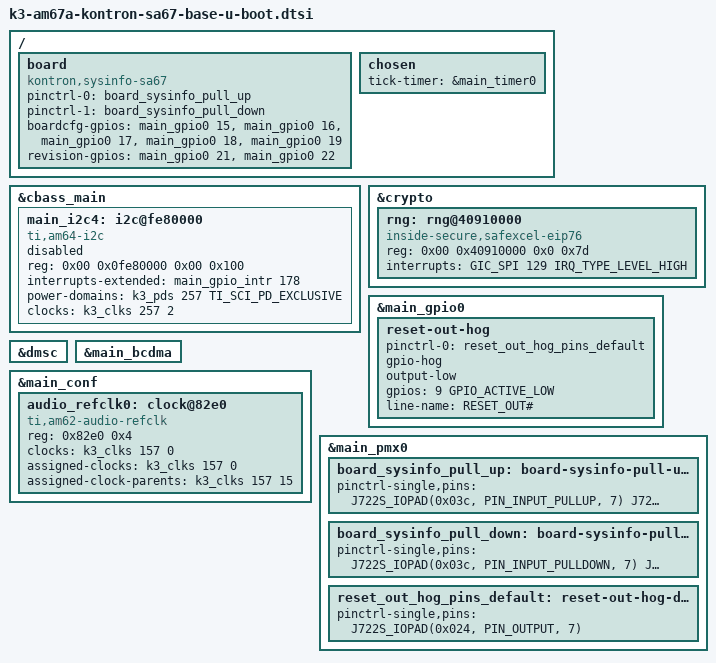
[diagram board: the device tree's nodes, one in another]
// SPDX-License-Identifier: GPL-2.0
/*
 * Copyright (c) 2025 Kontron Europe GmbH
 */

#include "k3-am67a-kontron-sa67-binman.dtsi"

/ {
	board {
		compatible = "kontron,sysinfo-sa67";

		pinctrl-names = "pull-up", "pull-down";
		pinctrl-0 = <&board_sysinfo_pull_up>;
		pinctrl-1 = <&board_sysinfo_pull_down>;

		boardcfg-gpios = <&main_gpio0 15 GPIO_ACTIVE_HIGH>,
				 <&main_gpio0 16 GPIO_ACTIVE_HIGH>,
				 <&main_gpio0 17 GPIO_ACTIVE_HIGH>,
				 <&main_gpio0 18 GPIO_ACTIVE_HIGH>,
				 <&main_gpio0 19 GPIO_ACTIVE_HIGH>;
		revision-gpios = <&main_gpio0 21 GPIO_ACTIVE_HIGH>,
				 <&main_gpio0 22 GPIO_ACTIVE_HIGH>;
		bootph-all;
	};

	chosen {
		tick-timer = &main_timer0;
	};
};

/* can be removed when upstream soc dtsi is updated */
&cbass_main {
	main_i2c4: i2c@fe80000 {
		compatible = "ti,am64-i2c", "ti,omap4-i2c";
		reg = <0x00 0x0fe80000 0x00 0x100>;
		interrupts-extended = <&main_gpio_intr 178>;
		#address-cells = <1>;
		#size-cells = <0>;
		power-domains = <&k3_pds 257 TI_SCI_PD_EXCLUSIVE>;
		clocks = <&k3_clks 257 2>;
		clock-names = "fck";
		status = "disabled";
	};
};

&crypto {
	rng: rng@40910000 {
		compatible = "inside-secure,safexcel-eip76";
		reg = <0x00 0x40910000 0x0 0x7d>;
		interrupts = <GIC_SPI 129 IRQ_TYPE_LEVEL_HIGH>;
	};
};

&main_gpio0 {
	reset-out-hog {
		pinctrl-names = "default";
		pinctrl-0 = <&reset_out_hog_pins_default>;
		gpio-hog;
		output-low;
		gpios = <9 GPIO_ACTIVE_LOW>;
		line-name = "RESET_OUT#";
	};
};

&dmsc {
	bootph-pre-ram;
};

&main_bcdma {
	bootph-pre-ram;
};

/* can be removed when upstream soc dtsi is updated */
&main_conf {
	audio_refclk0: clock@82e0 {
		compatible = "ti,am62-audio-refclk";
		reg = <0x82e0 0x4>;
		clocks = <&k3_clks 157 0>;
		assigned-clocks = <&k3_clks 157 0>;
		assigned-clock-parents = <&k3_clks 157 15>;
		#clock-cells = <0>;
	};
};

/* can be removed when upstream soc dtsi is updated */
&main_pmx0 {
	/delete-property/ pinctrl-single,gpio-range;
	/delete-node/ gpio-range;
};

&main_pmx0 {
	bootph-all;

	board_sysinfo_pull_up: board-sysinfo-pull-up-pins {
		pinctrl-single,pins = <
			J722S_IOPAD(0x03c, PIN_INPUT_PULLUP, 7)		/* (R22) GPNC9_AD0.GPIO0_15 */
			J722S_IOPAD(0x040, PIN_INPUT_PULLUP, 7)		/* (R23) GPNC9_AD1.GPIO0_16 */
			J722S_IOPAD(0x044, PIN_INPUT_PULLUP, 7)		/* (R26) GPNC9_AD2.GPIO0_17 */
			J722S_IOPAD(0x048, PIN_INPUT_PULLUP, 7)		/* (T27) GPNC9_AD3.GPIO0_18 */
			J722S_IOPAD(0x04c, PIN_INPUT_PULLUP, 7)		/* (T25) GPNC9_AD4.GPIO0_19 */
			J722S_IOPAD(0x050, PIN_INPUT_PULLUP, 7)		/* (T24) GPNC9_AD5.GPIO0_20 */
			J722S_IOPAD(0x054, PIN_INPUT_PULLUP, 7)		/* (T21) GPNC9_AD6.GPIO0_21 */
			J722S_IOPAD(0x058, PIN_INPUT_PULLUP, 7)		/* (T22) GPNC9_AD7.GPIO0_22 */
		>;
		bootph-all;
	};

	board_sysinfo_pull_down: board-sysinfo-pull-down-pins {
		pinctrl-single,pins = <
			J722S_IOPAD(0x03c, PIN_INPUT_PULLDOWN, 7)	/* (R22) GPNC9_AD0.GPIO0_15 */
			J722S_IOPAD(0x040, PIN_INPUT_PULLDOWN, 7)	/* (R23) GPNC9_AD1.GPIO0_16 */
			J722S_IOPAD(0x044, PIN_INPUT_PULLDOWN, 7)	/* (R26) GPNC9_AD2.GPIO0_17 */
			J722S_IOPAD(0x048, PIN_INPUT_PULLDOWN, 7)	/* (T27) GPNC9_AD3.GPIO0_18 */
			J722S_IOPAD(0x04c, PIN_INPUT_PULLDOWN, 7)	/* (T25) GPNC9_AD4.GPIO0_19 */
			J722S_IOPAD(0x050, PIN_INPUT_PULLDOWN, 7)	/* (T24) GPNC9_AD5.GPIO0_20 */
			J722S_IOPAD(0x054, PIN_INPUT_PULLDOWN, 7)	/* (T21) GPNC9_AD6.GPIO0_21 */
			J722S_IOPAD(0x058, PIN_INPUT_PULLDOWN, 7)	/* (T22) GPNC9_AD7.GPIO0_22 */
		>;
		bootph-all;
	};

	reset_out_hog_pins_default: reset-out-hog-default-pins {
		pinctrl-single,pins = <
			J722S_IOPAD(0x024, PIN_OUTPUT, 7)	/* (N27) GPIO0_9 */
		>;
	};
};
